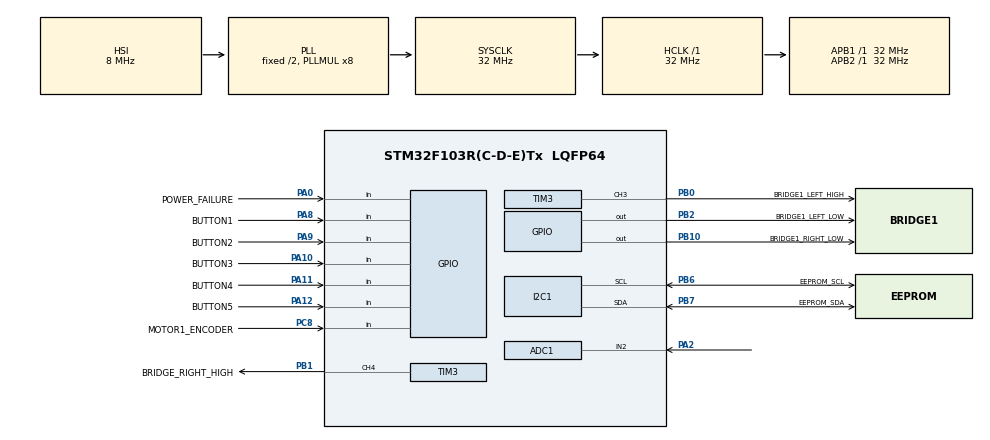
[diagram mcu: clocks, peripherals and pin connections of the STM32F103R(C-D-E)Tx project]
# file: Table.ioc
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ADC1.Channel-0\#ChannelRegularConversion=ADC_CHANNEL_2
ADC1.NbrOfConversionFlag=1
ADC1.Rank-0\#ChannelRegularConversion=1
ADC1.SamplingTime-0\#ChannelRegularConversion=ADC_SAMPLETIME_7CYCLES_5
ADC1.master=1
Dma.ADC1.2.Direction=DMA_PERIPH_TO_MEMORY
Dma.ADC1.2.Instance=DMA1_Channel1
Dma.ADC1.2.MemDataAlignment=DMA_MDATAALIGN_HALFWORD
Dma.ADC1.2.MemInc=DMA_MINC_ENABLE
Dma.ADC1.2.Mode=DMA_NORMAL
Dma.ADC1.2.PeriphDataAlignment=DMA_PDATAALIGN_HALFWORD
Dma.ADC1.2.PeriphInc=DMA_PINC_DISABLE
Dma.ADC1.2.Priority=DMA_PRIORITY_LOW
Dma.I2C1_RX.0.Direction=DMA_PERIPH_TO_MEMORY
Dma.I2C1_RX.0.Instance=DMA1_Channel7
Dma.I2C1_RX.0.MemDataAlignment=DMA_MDATAALIGN_BYTE
Dma.I2C1_RX.0.MemInc=DMA_MINC_ENABLE
Dma.I2C1_RX.0.Mode=DMA_NORMAL
Dma.I2C1_RX.0.PeriphDataAlignment=DMA_PDATAALIGN_BYTE
Dma.I2C1_RX.0.PeriphInc=DMA_PINC_DISABLE
Dma.I2C1_RX.0.Priority=DMA_PRIORITY_LOW
Dma.I2C1_TX.1.Direction=DMA_MEMORY_TO_PERIPH
Dma.I2C1_TX.1.Instance=DMA1_Channel6
Dma.I2C1_TX.1.MemDataAlignment=DMA_MDATAALIGN_BYTE
Dma.I2C1_TX.1.MemInc=DMA_MINC_ENABLE
Dma.I2C1_TX.1.Mode=DMA_NORMAL
Dma.I2C1_TX.1.PeriphDataAlignment=DMA_PDATAALIGN_BYTE
Dma.I2C1_TX.1.PeriphInc=DMA_PINC_DISABLE
Dma.I2C1_TX.1.Priority=DMA_PRIORITY_LOW
Dma.Request0=I2C1_RX
Dma.Request1=I2C1_TX
Dma.Request2=ADC1
Mcu.Family=STM32F1
Mcu.Name=STM32F103R(C-D-E)Tx
Mcu.Package=LQFP64
NVIC.ADC1_2_IRQn=true\:0\:0\:false\:false\:true\:true\:true
NVIC.DMA1_Channel1_IRQn=true\:0\:0\:false\:false\:true\:false\:true
NVIC.DMA1_Channel6_IRQn=true\:0\:0\:false\:false\:true\:false\:true
NVIC.DMA1_Channel7_IRQn=true\:0\:0\:false\:false\:true\:false\:true
NVIC.I2C1_ER_IRQn=true\:0\:0\:false\:false\:true\:true\:true
NVIC.I2C1_EV_IRQn=true\:0\:0\:false\:false\:true\:true\:true
NVIC.PriorityGroup=NVIC_PRIORITYGROUP_4
NVIC.TIM2_IRQn=true\:0\:0\:false\:false\:true\:true\:true
NVIC.TIM3_IRQn=true\:0\:0\:false\:false\:true\:true\:true
PA0-WKUP.GPIO_Label=POWER_FAILURE
PA0-WKUP.Signal=GPIO_Input
PA10.GPIO_Label=BUTTON3
PA10.GPIO_PuPd=GPIO_PULLUP
PA10.Signal=GPIO_Input
PA11.GPIO_Label=BUTTON4
PA11.GPIO_PuPd=GPIO_PULLUP
PA11.Signal=GPIO_Input
PA12.GPIO_Label=BUTTON5
PA12.GPIO_PuPd=GPIO_PULLUP
PA12.Signal=GPIO_Input
PA13.Mode=Serial_Wire
PA13.Signal=SYS_JTMS-SWDIO
PA14.Mode=Serial_Wire
PA14.Signal=SYS_JTCK-SWCLK
PA2.Signal=ADCx_IN2
PA8.GPIO_Label=BUTTON1
PA8.GPIO_PuPd=GPIO_PULLUP
PA8.Signal=GPIO_Input
PA9.GPIO_Label=BUTTON2
PA9.GPIO_PuPd=GPIO_PULLUP
PA9.Signal=GPIO_Input
PB0.GPIO_Label=BRIDGE1_LEFT_HIGH
PB0.Signal=S_TIM3_CH3
PB1.GPIO_Label=BRIDGE_RIGHT_HIGH
PB1.Signal=S_TIM3_CH4
PB10.GPIO_Label=BRIDGE1_RIGHT_LOW
PB10.Signal=GPIO_Output
PB2.GPIO_Label=BRIDGE1_LEFT_LOW
PB2.Signal=GPIO_Output
PB6.GPIO_Label=EEPROM_SCL
PB6.Mode=I2C
PB6.Signal=I2C1_SCL
PB7.GPIO_Label=EEPROM_SDA
PB7.Mode=I2C
PB7.Signal=I2C1_SDA
PC8.GPIO_Label=MOTOR1_ENCODER
PC8.Signal=GPIO_Input
ProjectManager.HeapSize=0x200
ProjectManager.StackSize=0x400
ProjectManager.TargetToolchain=STM32CubeIDE
RCC.ADCPresc=RCC_ADCPCLK2_DIV8
RCC.AHBFreq_Value=32000000
RCC.APB1Freq_Value=32000000
RCC.APB1TimFreq_Value=32000000
RCC.APB2Freq_Value=32000000
RCC.APB2TimFreq_Value=32000000
RCC.HCLKFreq_Value=32000000
RCC.PLLMUL=RCC_PLL_MUL8
RCC.SYSCLKFreq_VALUE=32000000
RCC.SYSCLKSource=RCC_SYSCLKSOURCE_PLLCLK
RCC.USBFreq_Value=32000000
SH.ADCx_IN2.0=ADC1_IN2,IN2
SH.S_TIM3_CH3.0=TIM3_CH3,PWM Generation3 CH3
SH.S_TIM3_CH4.0=TIM3_CH4,PWM Generation4 CH4
TIM2.AutoReloadPreload=TIM_AUTORELOAD_PRELOAD_ENABLE
TIM2.Period=32
TIM2.Prescaler=10000
TIM3.AutoReloadPreload=TIM_AUTORELOAD_PRELOAD_DISABLE
TIM3.Channel-PWM\ Generation3\ CH3=TIM_CHANNEL_3
TIM3.Channel-PWM\ Generation4\ CH4=TIM_CHANNEL_4
TIM3.Period=128
TIM3.Prescaler=16
TIM3.Pulse-PWM\ Generation3\ CH3=128
TIM3.Pulse-PWM\ Generation4\ CH4=128
VP_TIM2_VS_ClockSourceINT.Mode=Internal
VP_TIM3_VS_ClockSourceINT.Mode=Internal
board=custom

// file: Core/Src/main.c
/* USER CODE BEGIN Header */
/**
  ******************************************************************************
  * @file           : main.c
  * @brief          : Main program body
  ******************************************************************************
  * @attention
  *
  * <h2><center>&copy; Copyright (c) 2020 STMicroelectronics.
  * All rights reserved.</center></h2>
  *
  * This software component is licensed by ST under BSD 3-Clause license,
  * the "License"; You may not use this file except in compliance with the
  * License. You may obtain a copy of the License at:
  *                        opensource.org/licenses/BSD-3-Clause
  *
  ******************************************************************************
  */
/* USER CODE END Header */
#include "main.h"
#include "adc.h"
#include "dma.h"
#include "i2c.h"
#include "tim.h"
#include "gpio.h"

/* USER CODE BEGIN Includes */

#include <app.h>

/* USER CODE END Includes */

void SystemClock_Config(void);

int main(void)
{

  /* MCU Configuration--------------------------------------------------------*/

  /* Reset of all peripherals, Initializes the Flash interface and the Systick. */
  HAL_Init();

  /* Configure the system clock */
  SystemClock_Config();

  /* Initialize all configured peripherals */
  MX_GPIO_Init();
  MX_DMA_Init();
  MX_I2C1_Init();
  MX_ADC1_Init();
  MX_TIM2_Init();
  MX_TIM3_Init();

  /* Infinite loop */
  /* USER CODE BEGIN WHILE */

  appInit();
  HAL_TIM_Base_Start_IT(&htim2);

  while (1)
  {
    /* USER CODE END WHILE */

    /* USER CODE BEGIN 3 */
	  mainLoop();
  }
  /* USER CODE END 3 */
}

void SystemClock_Config(void)
{
  RCC_OscInitTypeDef RCC_OscInitStruct = {0};
  RCC_ClkInitTypeDef RCC_ClkInitStruct = {0};
  RCC_PeriphCLKInitTypeDef PeriphClkInit = {0};

  /** Initializes the RCC Oscillators according to the specified parameters
  * in the RCC_OscInitTypeDef structure.
  */
  RCC_OscInitStruct.OscillatorType = RCC_OSCILLATORTYPE_HSI;
  RCC_OscInitStruct.HSIState = RCC_HSI_ON;
  RCC_OscInitStruct.HSICalibrationValue = RCC_HSICALIBRATION_DEFAULT;
  RCC_OscInitStruct.PLL.PLLState = RCC_PLL_ON;
  RCC_OscInitStruct.PLL.PLLSource = RCC_PLLSOURCE_HSI_DIV2;
  RCC_OscInitStruct.PLL.PLLMUL = RCC_PLL_MUL8;
  if (HAL_RCC_OscConfig(&RCC_OscInitStruct) != HAL_OK)
  {
    Error_Handler();
  }
  /** Initializes the CPU, AHB and APB buses clocks
  */
  RCC_ClkInitStruct.ClockType = RCC_CLOCKTYPE_HCLK|RCC_CLOCKTYPE_SYSCLK
                              |RCC_CLOCKTYPE_PCLK1|RCC_CLOCKTYPE_PCLK2;
  RCC_ClkInitStruct.SYSCLKSource = RCC_SYSCLKSOURCE_PLLCLK;
  RCC_ClkInitStruct.AHBCLKDivider = RCC_SYSCLK_DIV1;
  RCC_ClkInitStruct.APB1CLKDivider = RCC_HCLK_DIV1;
  RCC_ClkInitStruct.APB2CLKDivider = RCC_HCLK_DIV1;

  if (HAL_RCC_ClockConfig(&RCC_ClkInitStruct, FLASH_LATENCY_1) != HAL_OK)
  {
    Error_Handler();
  }
  PeriphClkInit.PeriphClockSelection = RCC_PERIPHCLK_ADC;
  PeriphClkInit.AdcClockSelection = RCC_ADCPCLK2_DIV8;
  if (HAL_RCCEx_PeriphCLKConfig(&PeriphClkInit) != HAL_OK)
  {
    Error_Handler();
  }
}

void Error_Handler(void)
{
}

/************************ (C) COPYRIGHT STMicroelectronics *****END OF FILE****/
